# tsc_adc_ss register map
Vendor: Texas Instruments
Peripheral module from a debugger description file (folder am335x).
Registers are 32-bit, read-write, no defined reset value unless marked. A register's access mark holds for its fields unless they carry their own. Offsets are as the file gives them; lines under a group give offsets from that group; [hi:lo] are bit positions; {n}, {i} and the like mark numbered series; 'fields as' and 'values as' point back to an identical list; <NAME> marks a mode.

## tsc_adc_ss
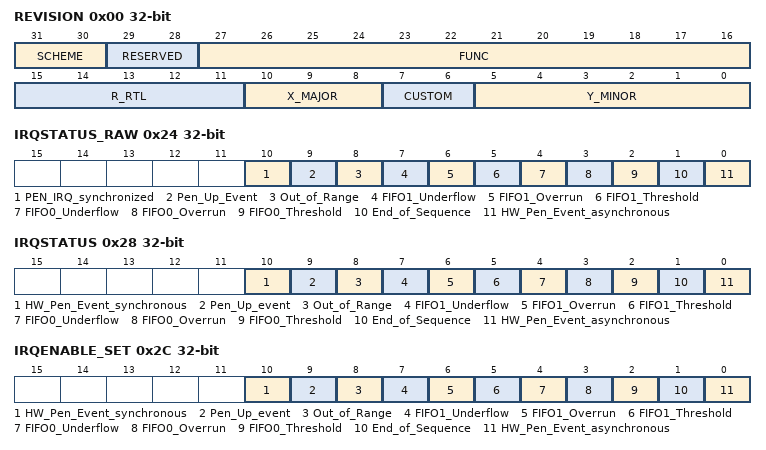
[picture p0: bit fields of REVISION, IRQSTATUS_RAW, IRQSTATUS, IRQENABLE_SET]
0x00 REVISION ro
  [31:30] SCHEME — HL 0.8 scheme
  [29:28] RESERVED — Always read as 0. Writes have no affect.
  [27:16] FUNC — Functional Number
  [15:11] R_RTL — RTL revision. Will vary depending on release.
  [10:8] X_MAJOR — Major revision.
  [7:6] CUSTOM — Custom revision.
  [5:0] Y_MINOR — Minor revision
0x10 SYSCONFIG
  [3:2] IdleMode — 00 = Force Idle (always acknowledges). 01 = No Idle Mode (never acknowledges). 10 = Smart-Idle Mode. 11 = Smart Idle with Wakeup.
0x24 IRQSTATUS_RAW — IRQ status (unmasked)
  [10] PEN_IRQ_synchronized — Write 0 = No action. Write 1 = Set event (debug). Read 0 = No event pending. Read 1 = Event pending.
  [9] Pen_Up_Event — Write 0 = No action. Write 1 = Set event (debug). Read 0 = No event pending. Read 1 = Event pending.
  [8] Out_of_Range — Write 0 = No action. Write 1 = Set event (debug). Read 0 = No event pending. Read 1 = Event pending.
  [7] FIFO1_Underflow — Write 0 = No action. Write 1 = Set event (debug). Read 0 = No event pending. Read 1 = Event pending.
  [6] FIFO1_Overrun — Write 0 = No action. Write 1 = Set event (debug). Read 0 = No event pending. Read 1 = Event pending.
  [5] FIFO1_Threshold — Write 0 = No action. Write 1 = Set event (debug). Read 0 = No event pending. Read 1 = Event pending.
  [4] FIFO0_Underflow — Write 0 = No action. Write 1 = Set event (debug). Read 0 = No event pending. Read 1 = Event pending.
  [3] FIFO0_Overrun — Write 0 = No action. Write 1 = Set event (debug). Read 0 = No event pending. Read 1 = Event pending.
  [2] FIFO0_Threshold — Write 0 = No action. Write 1 = Set event (debug). Read 0 = No event pending. Read 1 = Event pending.
  [1] End_of_Sequence — Write 0 = No action. Write 1 = Set event (debug). Read 0 = No event pending. Read 1 = Event pending.
  [0] HW_Pen_Event_asynchronous — Write 0 = No action. Write 1 = Set event (debug). Read 0 = No event pending. Read 1 = Event pending.
0x28 IRQSTATUS — IRQ status (masked)
  [10] HW_Pen_Event_synchronous — Write 0 = No action. Read 0 = No (enabled) event pending. Read 1 = Event pending. Write 1 = Clear (raw) event.
  [9] Pen_Up_event — Write 0 = No action. Read 0 = No (enabled) event pending. Read 1 = Event pending. Write 1 = Clear (raw) event.
  [8] Out_of_Range — Write 0 = No action. Read 0 = No (enabled) event pending. Read 1 = Event pending. Write 1 = Clear (raw) event.
  [7] FIFO1_Underflow — Write 0 = No action. Read 0 = No (enabled) event pending. Read 1 = Event pending. Write 1 = Clear (raw) event.
  [6] FIFO1_Overrun — Write 0 = No action. Read 0 = No (enabled) event pending. Read 1 = Event pending. Write 1 = Clear (raw) event.
  [5] FIFO1_Threshold — Write 0 = No action. Read 0 = No (enabled) event pending. Read 1 = Event pending. Write 1 = Clear (raw) event.
  [4] FIFO0_Underflow — Write 0 = No action. Read 0 = No (enabled) event pending. Read 1 = Event pending. Write 1 = Clear (raw) event.
  [3] FIFO0_Overrun — Write 0 = No action. Read 0 = No (enabled) event pending. Read 1 = Event pending. Write 1 = Clear (raw) event.
  [2] FIFO0_Threshold — Write 0 = No action. Read 0 = No (enabled) event pending. Read 1 = Event pending. Write 1 = Clear (raw) event.
  [1] End_of_Sequence — Write 0 = No action. Read 0 = No (enabled) event pending. Read 1 = Event pending. Write 1 = Clear (raw) event.
  [0] HW_Pen_Event_asynchronous — Write 0 = No action. Read 0 = No (enabled) event pending. Read 1 = Event pending. Write 1 = Clear (raw) event.
0x2C IRQENABLE_SET — IRQ enable set bits
  [10] HW_Pen_Event_synchronous — Write 0 = No action. Read 0 = Interrupt disabled (masked). Read 1 = Interrupt enabled. Write 1 = Enable interrupt.
  [9] Pen_Up_event — Write 0 = No action. Read 0 = Interrupt disabled (masked). Read 1 = Interrupt enabled. Write 1 = Enable interrupt.
  [8] Out_of_Range — Write 0 = No action. Read 0 = Interrupt disabled (masked). Read 1 = Interrupt enabled. Write 1 = Enable interrupt.
  [7] FIFO1_Underflow — Write 0 = No action. Read 0 = Interrupt disabled (masked). Read 1 = Interrupt enabled. Write 1 = Enable interrupt.
  [6] FIFO1_Overrun — Write 0 = No action. Read 0 = Interrupt disabled (masked). Read 1 = Interrupt enabled. Write 1 = Enable interrupt.
  [5] FIFO1_Threshold — Write 0 = No action. Read 0 = Interrupt disabled (masked). Read 1 = Interrupt enabled. Write 1 = Enable interrupt.
  [4] FIFO0_Underflow — Write 0 = No action. Read 0 = Interrupt disabled (masked). Read 1 = Interrupt enabled. Write 1 = Enable interrupt.
  [3] FIFO0_Overrun — Write 0 = No action. Read 0 = Interrupt disabled (masked). Read 1 = Interrupt enabled. Write 1 = Enable interrupt.
  [2] FIFO0_Threshold — Write 0 = No action. Read 0 = Interrupt disabled (masked). Read 1 = Interrupt enabled. Write 1 = Enable interrupt.
  [1] End_of_Sequence — Write 0 = No action. Read 0 = Interrupt disabled (masked). Read 1 = Interrupt enabled. Write 1 = Enable interrupt.
  [0] HW_Pen_Event_asynchronous — Write 0 = No action. Read 0 = Interrupt disabled (masked). Read 1 = Interrupt enabled. Write 1 = Enable interrupt.
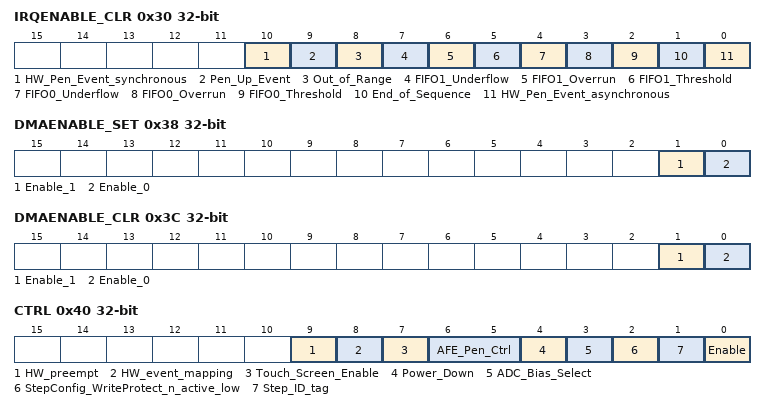
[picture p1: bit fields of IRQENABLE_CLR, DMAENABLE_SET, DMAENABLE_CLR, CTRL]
0x30 IRQENABLE_CLR — IRQ enable clear bits
  [10] HW_Pen_Event_synchronous — Write 0 = No action. Read 0 = Interrupt disabled (masked). Read 1 = Interrupt enabled. Write 1 = Disable interrupt.
  [9] Pen_Up_Event — Write 0 = No action. Read 0 = Interrupt disabled (masked). Read 1 = Interrupt enabled. Write 1 = Disable interrupt.
  [8] Out_of_Range — Write 0 = No action. Read 0 = Interrupt disabled (masked). Read 1 = Interrupt enabled. Write 1 = Disable interrupt.
  [7] FIFO1_Underflow — Write 0 = No action. Read 0 = Interrupt disabled (masked). Read 1 = Interrupt enabled. Write 1 = Disable interrupt.
  [6] FIFO1_Overrun — Write 0 = No action. Read 0 = Interrupt disabled (masked). Read 1 = Interrupt enabled. Write 1 = Disable interrupt.
  [5] FIFO1_Threshold — Write 0 = No action. Read 0 = Interrupt disabled (masked). Read 1 = Interrupt enabled. Write 1 = Disable interrupt.
  [4] FIFO0_Underflow — Write 0 = No action. Read 0 = Interrupt disabled (masked). Read 1 = Interrupt enabled. Write 1 = Disable interrupt.
  [3] FIFO0_Overrun — Write 0 = No action. Read 0 = Interrupt disabled (masked). Read 1 = Interrupt enabled. Write 1 = Disable interrupt.
  [2] FIFO0_Threshold — Write 0 = No action. Read 0 = Interrupt disabled (masked). Read 1 = Interrupt enabled. Write 1 = Disable interrupt.
  [1] End_of_Sequence — Write 0 = No action. Read 0 = Interrupt disabled (masked). Read 1 = Interrupt enabled. Write 1 = Disable interrupt.
  [0] HW_Pen_Event_asynchronous — Write 0 = No action. Read 0 = Interrupt disabled (masked). Read 1 = Interrupt enabled. Write 1 = Disable interrupt.
0x34 IRQWAKEUP — IRQ wakeup enable
  [0] WAKEEN0 — Wakeup generation for HW Pen event. 0 = Wakeup disabled. 1 = Wakeup enabled.
0x38 DMAENABLE_SET — Per-Line DMA set
  [1] Enable_1 — Enable DMA request FIFO 1. Write 0 = No action. Read 0 = DMA line disabled. Read 1 = DMA line enabled. Write 1 = Enable DMA line.
  [0] Enable_0 — Enable DMA request FIFO 0. Write 0 = No action. Read 0 = DMA line disabled. Read 1 = DMA line enabled. Write 1 = Enable DMA line.
0x3C DMAENABLE_CLR — Per-Line DMA clr
  [1] Enable_1 — Disable DMA request FIFO 1. Write 0 = No action. Read 0 = DMA line disabled. Read 1 = DMA line enabled. Write 1 = Disable DMA line.
  [0] Enable_0 — Disable DMA request FIFO 0. Write 0 = No action. Read 0 = DMA line disabled. Read 1 = DMA line enabled. Write 1 = Disable DMA line.
0x40 CTRL access per field — @TSC_ADC_SS Control Register
  [9] HW_preempt rw — 0 = SW steps are not pre-empted by HW events. 1 = SW steps are pre-empted by HW events
  [8] HW_event_mapping rw — 0 = Map HW event to Pen touch irq (from AFE). 1 = Map HW event to HW event input.
  [7] Touch_Screen_Enable rw — 0 = Touchscreen transistors disabled. 1 = Touchscreen transistors enabled
  [6:5] AFE_Pen_Ctrl rw — These two bits are sent directly to the AFE Pen Ctrl inputs. Bit 6 controls the Wiper touch (5 wire modes)Bit 5 controls the X+ touch (4 wire modes)User also needs to make sure the ground path is connected properly for pen interrupt to occur (using the StepConfig registers)Refer to section 4 interrupts for more information
  [4] Power_Down rw — ADC Power Down control. 0 = AFE is powered up (default). 1 = Write 1 to power down AFE (the tsc_adc_ss enable (bit 0) should also be set to off)
  [3] ADC_Bias_Select rw — Select Bias to AFE. 0 = Internal. 1 = Reserved.
  [2] StepConfig_WriteProtect_n_active_low rw — 0 = Step configuration registers are protected (not writable). 1 = Step configuration registers are not protected (writable).
  [1] Step_ID_tag rw — Writing 1 to this bit will store the Step ID number with the captured ADC data in the FIFO. 0 = Write zeroes. 1 = Store the channel ID tag.
  [0] Enable rw — TSC_ADC_SS module enable bit. After programming all the steps and configuration registers, write a 1to this bit to turn on TSC_ADC_SS. Writing a 0 will disable the module (after the current conversion).
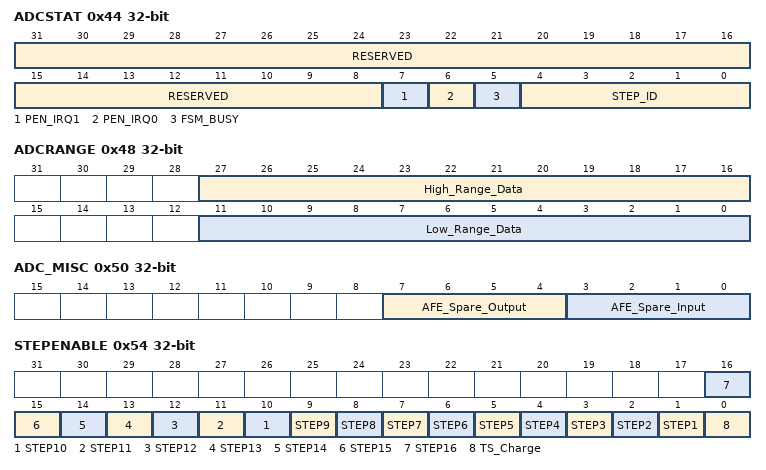
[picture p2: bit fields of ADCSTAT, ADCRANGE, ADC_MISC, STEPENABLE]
0x44 ADCSTAT ro — General Status bits @TSC_ADC_SS_Sequencer_Status Register
  [31:8] RESERVED
  [7] PEN_IRQ1 — PEN_IRQ[1] status
  [6] PEN_IRQ0 — PEN_IRQ[0] status
  [5] FSM_BUSY — Status of OCP FSM and ADC FSM. 0 = Idle. 1 = Busy.
  [4:0] STEP_ID — Encoded values:. 10000 = Idle. 10001 = Charge. 00000 = Step 1. 00001 = Step 2. 00010 = Step 3. 00011 = Step 4. 00100 = Step 5. 00101 = Step 6. 00110 = Step 7. 00111 = Step 8. 01000 = Step 9. 01001 = Step 10. 01010 = Step 11. 01011 = Step 12. 01100 = Step 13. 01101 = Step 14. 01110 = Step 15. 01111 = Step 16.
0x48 ADCRANGE access not given — High and Low Range Threshold@TSC_ADC_SS_Range_Check Register
  [27:16] High_Range_Data rw — Sampled ADC data is compared to this value. If the sampled data is greater than the value, then an interrupt is generated.
  [11:0] Low_Range_Data rw — Sampled ADC data is compared to this value. If the sampled data is less than the value, then an interrupt is generated.
0x4C ADC_CLKDIV access per field — ADC clock divider register@TSC_ADC_SS_Clock_Divider Register
  [15:0] ADC_ClkDiv rw — The input ADC clock will be divided by this value and sent to the AFE. Program to the value minus 1
0x50 ADC_MISC access per field — AFE misc debug@TSC_ADC_SS_MISC Register
  [7:4] AFE_Spare_Output ro — Connected to AFE Spare Output pins. Reserved in normal operation.
  [3:0] AFE_Spare_Input rw — Connected to AFE Spare Input pins. Reserved in normal operation.
0x54 STEPENABLE access per field
  [n] STEP{n} rw (n=1..16) — Enable step {n}
  [0] TS_Charge rw — Enable TS Charge step
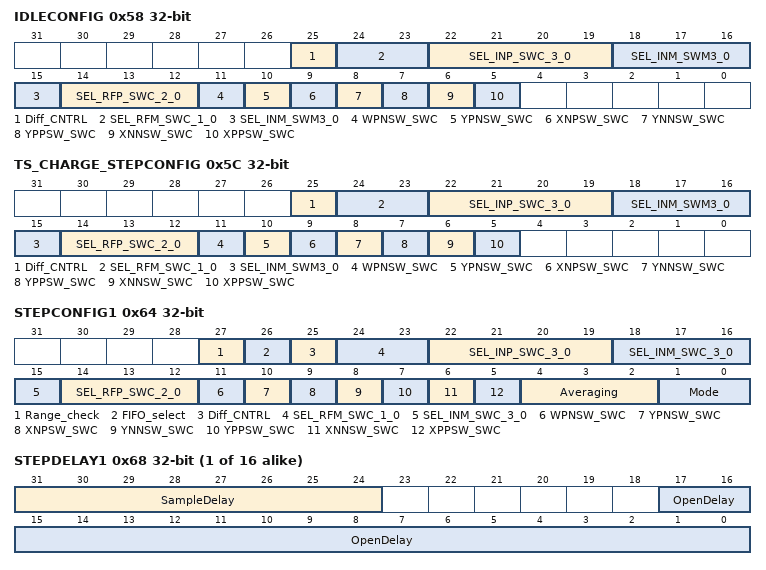
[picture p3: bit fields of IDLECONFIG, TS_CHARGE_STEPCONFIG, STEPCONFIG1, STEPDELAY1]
0x58 IDLECONFIG — Idle Step configuration@TSC_ADC_SS_IDLE_StepConfig Register
  [25] Diff_CNTRL — Differential Control Pin. 0 = Single Ended. 1 = Differential Pair Enable.
  [24:23] SEL_RFM_SWC_1_0 — SEL_RFM pins SW configuration. 00 = VSSA_ADC. 01 = XNUR. 10 = YNLR. 11 = VREFN.
  [22:19] SEL_INP_SWC_3_0 — SEL_INP pins SW configuration. 0000 = Channel 1. 0111 = Channel 8. 1xxx = VREFN.
  [18:15] SEL_INM_SWM3_0 — SEL_INM pins for neg differential. 0000 = Channel 1. 0111 = Channel 8. 1xxx = VREFN.
  [14:12] SEL_RFP_SWC_2_0 — SEL_RFP pins SW configuration. 000 = VDDA_ADC. 001 = XPUL. 010 = YPLL. 011 = VREFP. 1xx = Reserved.
  [11] WPNSW_SWC — WPNSW pin SW configuration
  [10] YPNSW_SWC — YPNSW pin SW configuration
  [9] XNPSW_SWC — XNPSW pin SW configuration
  [8] YNNSW_SWC — YNNSW pin SW configuration
  [7] YPPSW_SWC — YPPSW pin SW configuration
  [6] XNNSW_SWC — XNNSW pin SW configuration
  [5] XPPSW_SWC — XPPSW pin SW configuration
0x5C TS_CHARGE_STEPCONFIG — TS Charge StepConfiguration@TSC_ADC_SS_TS_Charge_StepConfig Register
  [25] Diff_CNTRL — Differential Control Pin. 0 = Single Ended. 1 = Differential Pair Enable.
  [24:23] SEL_RFM_SWC_1_0 — SEL_RFM pins SW configuration. 00 = VSSA. 01 = XNUR. 10 = YNLR. 11 = VREFN.
  [22:19] SEL_INP_SWC_3_0 — SEL_INP pins SW configuration. 0000 = Channel 1. 0111 = Channel 8. 1xxx = VREFN.
  [18:15] SEL_INM_SWM3_0 — SEL_INM pins for neg differential. 0000 = Channel 1. 0111 = Channel 8. 1xxx = VREFN.
  [14:12] SEL_RFP_SWC_2_0 — SEL_RFP pins SW configuration. 000 = VDDA. 001 = XPUL. 010 = YPLL. 011 = VREFP. 1xx = INTREF.
  [11] WPNSW_SWC — WPNSW pin SW configuration
  [10] YPNSW_SWC — YPNSW pin SW configuration
  [9] XNPSW_SWC — XNPSW pin SW configuration
  [8] YNNSW_SWC — YNNSW pin SW configuration
  [7] YPPSW_SWC — YPPSW pin SW configuration
  [6] XNNSW_SWC — XNNSW pin SW configuration
  [5] XPPSW_SWC — XPPSW pin SW configuration
0x60 TS_CHARGE_DELAY — TS Charge Delay Register@TSC_ADC_SS_TS_Charge_StepDelay Register
  [17:0] OpenDelay — Program the # of ADC clock cycles to wait between applying the step configuration registers and going back to the IDLE state. (Value must be greater than 0.)
0x64 STEPCONFIG1 — Step Configuration 1
  [27] Range_check — 0 = Disable out-of-range check. 1 = Compare ADC data with range check register.
  [26] FIFO_select — Sampled data will be stored in FIFO. 0 = FIFO. 1 = FIFO 1.
  [25] Diff_CNTRL — Differential Control Pin
  [24:23] SEL_RFM_SWC_1_0 — SEL_RFM pins SW configuration
  [22:19] SEL_INP_SWC_3_0 — SEL_INP pins SW configuration
  [18:15] SEL_INM_SWC_3_0 — SEL_INM pins for negative differential
  [14:12] SEL_RFP_SWC_2_0 — SEL_RFP pins SW configuration
  [11] WPNSW_SWC — WPNSW pin SW configuration
  [10] YPNSW_SWC — YPNSW pin SW configuration
  [9] XNPSW_SWC — XNPSW pin SW configuration
  [8] YNNSW_SWC — YNNSW pin SW configuration
  [7] YPPSW_SWC — YPPSW pin SW configuration
  [6] XNNSW_SWC — XNNSW pin SW configuration
  [5] XPPSW_SWC — XPPSW pin SW configuration
  [4:2] Averaging — Number of samplings to average: 000 = No average. 001 = 2 samples average. 010 = 4 samples average. 011 = 8 samples average. 100 = 16 samples average.
  [1:0] Mode — 00 = SW enabled, one-shot. 01 = SW enabled, continuous. 10 = HW synchronized, one-shot. 11 = HW synchronized, continuous.
{0x60+8i} STEPDELAY{i} (i=1..16) — Step Delay Register {i}
  [31:24] SampleDelay — This register will control the number of ADC clock cycles to sample (hold SOC high). Any value programmed here will be added to the minimum requirement of 1 clock cycle.
  [17:0] OpenDelay — Program the number of ADC clock cycles to wait after applying the step configuration registers and before sending the start of ADC conversion
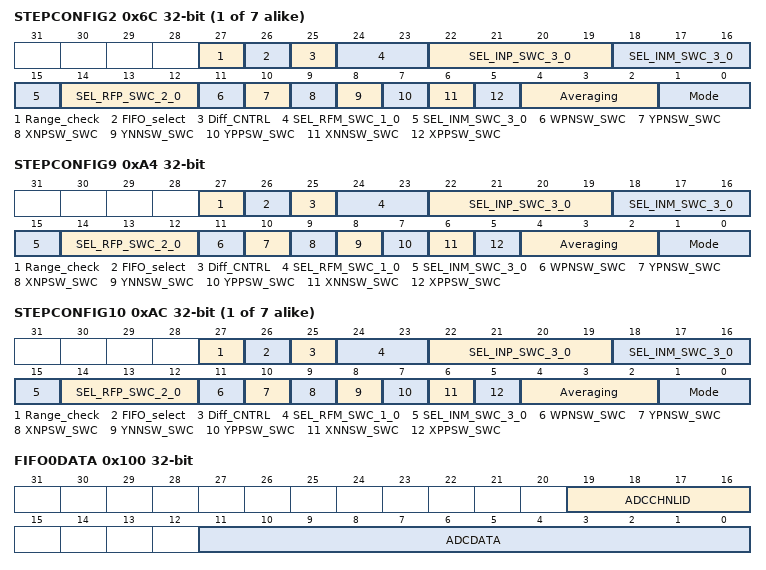
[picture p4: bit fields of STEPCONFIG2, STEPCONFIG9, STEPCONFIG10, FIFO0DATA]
{0x5C+8i} STEPCONFIG{i} (i=2..8) — Step Configuration {i}
  [27] Range_check — 0 = Disable out-of-range check. 1 = Compare ADC data with range check register.
  [26] FIFO_select — Sampled data will be stored in FIFO. 0 = FIFO. 1 = FIFO1.
  [25] Diff_CNTRL — Differential Control Pin
  [24:23] SEL_RFM_SWC_1_0 — SEL_RFM pins SW configuration
  [22:19] SEL_INP_SWC_3_0 — SEL_INP pins SW configuration
  [18:15] SEL_INM_SWC_3_0 — SEL_INM pins for negative differential
  [14:12] SEL_RFP_SWC_2_0 — SEL_RFP pins SW configuration
  [11] WPNSW_SWC — WPNSW pin SW configuration
  [10] YPNSW_SWC — YPNSW pin SW configuration
  [9] XNPSW_SWC — XNPSW pin SW configuration
  [8] YNNSW_SWC — YNNSW pin SW configuration
  [7] YPPSW_SWC — YPPSW pin SW configuration
  [6] XNNSW_SWC — XNNSW pin SW configuration
  [5] XPPSW_SWC — XPPSW pin SW configuration
  [4:2] Averaging — Number of samples to average: 000 = No average. 001 = 2 samples average. 010 = 4 samples average. 011 = 8 samples average. 100 = 16 samples average.
  [1:0] Mode — 00 = SW enabled, one-shot. 01 = SW enabled, continuous. 10 = HW synchronized, one-shot. 11 = HW synchronized, continuous.
0xA4 STEPCONFIG9 — Step Configuration 9
  [27] Range_check — 0 = Disable out-of-range check. 1 = Compare ADC data with range check register.
  [26] FIFO_select — Sampled data will be stored in FIFO. 0 = FIFO 1. = FIFO1.
  [25] Diff_CNTRL — Differential Control Pin
  [24:23] SEL_RFM_SWC_1_0 — SEL_RFM pins SW configuration
  [22:19] SEL_INP_SWC_3_0 — SEL_INP pins SW configuration
  [18:15] SEL_INM_SWC_3_0 — SEL_INM pins for negative differential
  [14:12] SEL_RFP_SWC_2_0 — SEL_RFP pins SW configuration
  [11] WPNSW_SWC — WPNSW pin SW configuration
  [10] YPNSW_SWC — YPNSW pin SW configuration
  [9] XNPSW_SWC — XNPSW pin SW configuration
  [8] YNNSW_SWC — YNNSW pin SW configuration
  [7] YPPSW_SWC — YPPSW pin SW configuration
  [6] XNNSW_SWC — XNNSW pin SW configuration
  [5] XPPSW_SWC — XPPSW pin SW configuration
  [4:2] Averaging — Number of samples to average: 000 = No average. 001 = 2 samples average. 010 = 4 samples average. 011 = 8 samples average. 100 = 16 samples average.
  [1:0] Mode — 00 = SW enabled, one-shot. 01 = SW enabled, continuous. 10 = HW synchronized, one-shot. 11 = HW synchronized, continuous.
{0x5C+8i} STEPCONFIG{i} (i=10..16) — Step Configuration {i}
  fields as STEPCONFIG2
0xE4 FIFO0COUNT ro — FIFO0 word count@TSC_ADC_SS_FIFO0 Word Count Register
  [6:0] Words_in_FIFO0 — Number of words currently in the FIFO0
0xE8 FIFO0THRESHOLD access per field — FIFO0 Threshold trigger@TSC_ADC_SS_FIFO0 Threshold Level Register
  [5:0] FIFO0_threshold_Level rw — Program the desired FIFO0 data sample level to reach before generating interrupt to CPU (program to value minus 1)
0xEC DMA0REQ access per field — FIFO0 DMA req0 trigger@TSC_ADC_SS_FIFO0 DMA REQUEST Register
  [5:0] DMA_Request_Level rw — Number of words in FIFO0 before generating a DMA request (program to value minus 1)
0xF0 FIFO1COUNT ro — FIFO1 word count@TSC_ADC_SS_FIFO1 Word Count Register
  [6:0] Words_in_FIFO0 — Number of words currently in the FIFO0
0xF4 FIFO1THRESHOLD access per field — FIFO1 Threshold trigger@TSC_ADC_SS_FIFO1 Threshold Level Register
  fields as FIFO0THRESHOLD
0xF8 DMA1REQ access per field — FIFO1 DMA req1 trigger@TSC_ADC_SS_FIFO1 DMA Request Register
  fields as DMA0REQ
0x100 FIFO0DATA ro — ADC_ FIFO0 _READ Data @TSC_ADC_SS_FIFO0 READ Register
  [19:16] ADCCHNLID — Optional ID tag of channel that captured the data. If tag option is disabled, these bits will be 0.
  [11:0] ADCDATA — 12 bit sampled ADC converted data value stored in FIFO 0.
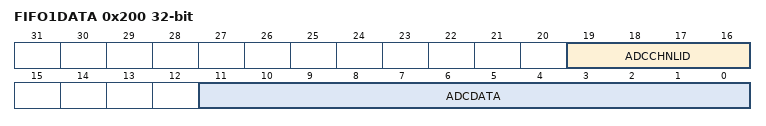
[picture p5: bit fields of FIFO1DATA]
0x200 FIFO1DATA ro — ADC FIFO1_READ Data@TSC_ADC_SS_FIFO1 READ Register
  [19:16] ADCCHNLID — Optional ID tag of channel that captured the data. If tag option is disabled, these bits will be 0.
  [11:0] ADCDATA — 12 bit sampled ADC converted data value stored in FIFO 1.
